# QSPI register map
Vendor: Texas Instruments
Peripheral module from a debugger description file (folder 66AK2G0x_66AK2G1x).
Registers are 32-bit, access not given, reset 0x0 unless marked. A register's access mark holds for its fields unless they carry their own. Offsets are as the file gives them; lines under a group give offsets from that group; [hi:lo] are bit positions; {n}, {i} and the like mark numbered series; 'fields as' and 'values as' point back to an identical list; <NAME> marks a mode.

## QSPI
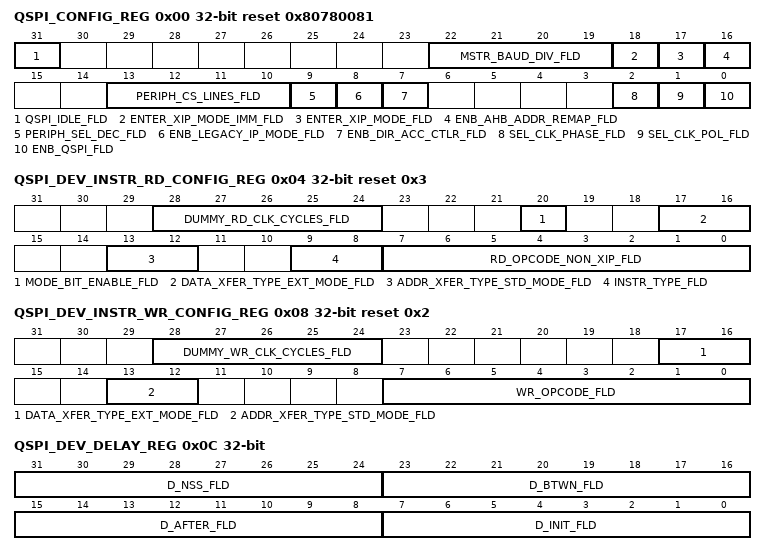
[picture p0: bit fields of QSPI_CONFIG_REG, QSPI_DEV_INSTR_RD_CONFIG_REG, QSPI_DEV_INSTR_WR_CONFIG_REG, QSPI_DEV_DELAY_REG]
0x00 QSPI_CONFIG_REG access per field reset 0x80780081
  [31] QSPI_IDLE_FLD ro — Serial interface and QSPI pipeline is IDLE:
  [22:19] MSTR_BAUD_DIV_FLD rw — Master Mode Baud Rate Divisor (2 to 32): Where Baud Devisor (BD) is:
  [18] ENTER_XIP_MODE_IMM_FLD rw — Enter XIP Mode immediately:
  [17] ENTER_XIP_MODE_FLD rw — Enter XIP Mode on next READ:
  [16] ENB_AHB_ADDR_REMAP_FLD rw — Enable AHB Address Re-mapping (Direct Access Mode Only):
  [13:10] PERIPH_CS_LINES_FLD rw — Peripheral Chip Select Lines:else ss[3:0] directly drives n_ss_out[3:0] .
  [9] PERIPH_SEL_DEC_FLD rw — Peripheral select decode:
  [8] ENB_LEGACY_IP_MODE_FLD rw — Legacy QSPI Mode Enable:
  [7] ENB_DIR_ACC_CTLR_FLD rw — Enable Direct Access Controller:
  [2] SEL_CLK_PHASE_FLD rw — Clock phase:
  [1] SEL_CLK_POL_FLD rw — Clock polarity outside SPI word:
  [0] ENB_QSPI_FLD rw — QSPI Enable:
0x04 QSPI_DEV_INSTR_RD_CONFIG_REG access per field reset 0x3
  [28:24] DUMMY_RD_CLK_CYCLES_FLD rw — Dummy Read Clock Cycles:
  [20] MODE_BIT_ENABLE_FLD rw — Mode Bit Enable:
  [17:16] DATA_XFER_TYPE_EXT_MODE_FLD rw — Data Transfer Type for Standard SPI modes:
  [13:12] ADDR_XFER_TYPE_STD_MODE_FLD rw — Address Transfer Type for Standard SPI modes:
  [9:8] INSTR_TYPE_FLD rw — Instruction Type:
  [7:0] RD_OPCODE_NON_XIP_FLD rw — Read Opcode in non-XIP mode:
0x08 QSPI_DEV_INSTR_WR_CONFIG_REG access per field reset 0x2
  [28:24] DUMMY_WR_CLK_CYCLES_FLD rw — Dummy Write Clock Cycles:
  [17:16] DATA_XFER_TYPE_EXT_MODE_FLD rw — Data Transfer Type for Standard SPI modes:
  [13:12] ADDR_XFER_TYPE_STD_MODE_FLD rw — Address Transfer Type for Standard SPI modes:
  [7:0] WR_OPCODE_FLD rw — Write Opcode:
0x0C QSPI_DEV_DELAY_REG rw
  [31:24] D_NSS_FLD — Clock Delay for Chip Select Deassert:
  [23:16] D_BTWN_FLD — Clock Delay for Chip Select Deactivation:
  [15:8] D_AFTER_FLD — Clock Delay for Last Transaction Bit:
  [7:0] D_INIT_FLD — Clock Delay with n_ss_out:
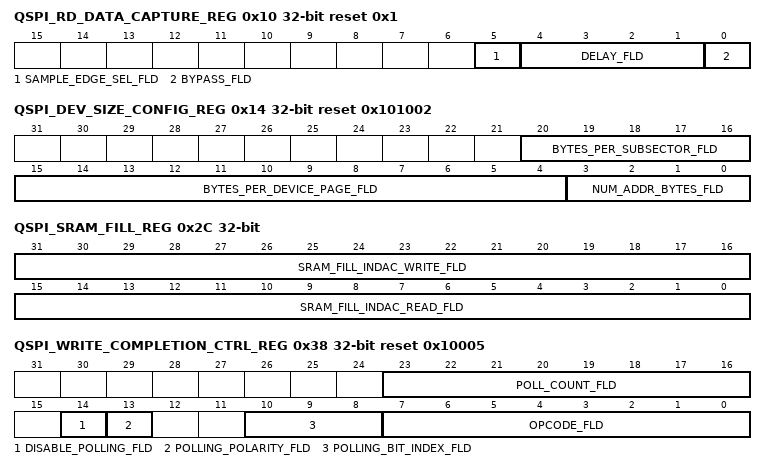
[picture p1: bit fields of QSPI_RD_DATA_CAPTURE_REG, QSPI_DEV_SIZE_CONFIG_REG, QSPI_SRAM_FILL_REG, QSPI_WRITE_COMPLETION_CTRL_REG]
0x10 QSPI_RD_DATA_CAPTURE_REG access per field reset 0x1
  [5] SAMPLE_EDGE_SEL_FLD rw — Sample edge selection (of the flash memory data outputs).
  [4:1] DELAY_FLD rw — Read Delay:
  [0] BYPASS_FLD rw — Bypass:
0x14 QSPI_DEV_SIZE_CONFIG_REG access per field reset 0x101002
  [20:16] BYTES_PER_SUBSECTOR_FLD rw — Number of Bytes per Block:
  [15:4] BYTES_PER_DEVICE_PAGE_FLD rw — Number of Bytes per Device Page:
  [3:0] NUM_ADDR_BYTES_FLD rw — Number of address Bytes:
0x18 QSPI_SRAM_PARTITION_CFG_REG access per field reset 0x80
  [7:0] ADDR_FLD rw — Indirect Read Partition Size:
0x1C QSPI_IND_AHB_ADDR_TRIGGER_REG rw
  [31:0] ADDR_FLD — Indirect Trigger Address:
0x24 QSPI_REMAP_ADDR_REG rw
  [31:0] VALUE_FLD — Remap Address Register:
0x28 QSPI_MODE_BIT_CONFIG_REG access per field
  [7:0] MODE_FLD rw — Mode Bits:
0x2C QSPI_SRAM_FILL_REG ro
  [31:16] SRAM_FILL_INDAC_WRITE_FLD — SRAM Fill Level (Indirect Write Partition):
  [15:0] SRAM_FILL_INDAC_READ_FLD — SRAM Fill Level (Indirect Read Partition):
0x30 QSPI_TX_THRESH_REG access per field reset 0x1
  [3:0] LEVEL_FLD rw — Level TX FIFO not full:
0x34 QSPI_RX_THRESH_REG access per field reset 0x1
  [3:0] LEVEL_FLD rw — Level RX FIFO not empty:
0x38 QSPI_WRITE_COMPLETION_CTRL_REG access per field reset 0x10005
  [23:16] POLL_COUNT_FLD rw — Polling Count:
  [14] DISABLE_POLLING_FLD rw — Disable Polling:
  [13] POLLING_POLARITY_FLD rw — Polling Polarity:
  [10:8] POLLING_BIT_INDEX_FLD rw — Polling Bit Index:
  [7:0] OPCODE_FLD rw — Opcode:
0x3C QSPI_NO_OF_POLLS_BEF_EXP_REG rw reset 0xFFFFFFFF
  [31:0] NO_OF_POLLS_BEF_EXP_FLD — Defines the numbers of polls cycles after which polling expiration interrupt is generated. NOTE: Max no of polls &gt; 2(TX_FIFO_DEPTH – 1) + 1. Polling cycles are queued in FIFO, so expiration requires to make FIFO empty.
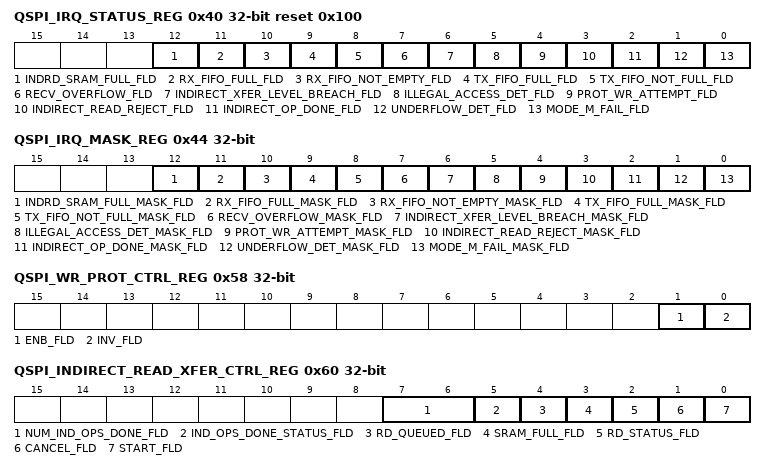
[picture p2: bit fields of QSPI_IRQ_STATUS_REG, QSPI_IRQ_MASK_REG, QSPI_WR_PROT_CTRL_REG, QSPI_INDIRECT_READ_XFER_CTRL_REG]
0x40 QSPI_IRQ_STATUS_REG access per field reset 0x100
  [12] INDRD_SRAM_FULL_FLD rw — Indirect Read Partition overflow:
  [11] RX_FIFO_FULL_FLD rw — Small RX FIFO full:
  [10] RX_FIFO_NOT_EMPTY_FLD rw — Small RX FIFO not empty:
  [9] TX_FIFO_FULL_FLD rw — Small TX FIFO full:
  [8] TX_FIFO_NOT_FULL_FLD rw — Small TX FIFO not full:
  [7] RECV_OVERFLOW_FLD rw — Receive Overflow:
  [6] INDIRECT_XFER_LEVEL_BREACH_FLD rw — Transfer Watermark Breach:
  [5] ILLEGAL_ACCESS_DET_FLD rw — Illegal AHB Access Detected:
  [4] PROT_WR_ATTEMPT_FLD rw — Protected Area Write Attempt:
  [3] INDIRECT_READ_REJECT_FLD rw — Indirect Read Reject:
  [2] INDIRECT_OP_DONE_FLD rw — Indirect Operation Complete:
  [1] UNDERFLOW_DET_FLD rw — Underflow Detected:
  [0] MODE_M_FAIL_FLD rw — Mode M Failure:
0x44 QSPI_IRQ_MASK_REG access per field
  [12] INDRD_SRAM_FULL_MASK_FLD rw — Indirect Read Partition overflow mask
  [11] RX_FIFO_FULL_MASK_FLD rw — Small RX FIFO full Mask
  [10] RX_FIFO_NOT_EMPTY_MASK_FLD rw — Small RX FIFO not empty Mask
  [9] TX_FIFO_FULL_MASK_FLD rw — Small TX FIFO full Mask
  [8] TX_FIFO_NOT_FULL_MASK_FLD rw — Small TX FIFO not full Mask
  [7] RECV_OVERFLOW_MASK_FLD rw — Receive Overflow Mask
  [6] INDIRECT_XFER_LEVEL_BREACH_MASK_FLD rw — Transfer Watermark Breach Mask
  [5] ILLEGAL_ACCESS_DET_MASK_FLD rw — Illegal Access Detected Mask
  [4] PROT_WR_ATTEMPT_MASK_FLD rw — Protected Area Write Attempt Mask
  [3] INDIRECT_READ_REJECT_MASK_FLD rw — Indirect Read Reject Mask
  [2] INDIRECT_OP_DONE_MASK_FLD rw — Indirect Complete Mask
  [1] UNDERFLOW_DET_MASK_FLD rw — Underflow Detected Mask
  [0] MODE_M_FAIL_MASK_FLD rw — Mode M Failure Mask
0x50 QSPI_LOWER_WR_PROT_REG rw
  [31:0] SUBSECTOR_FLD — Lower Block Number:
0x54 QSPI_UPPER_WR_PROT_REG rw
  [31:0] SUBSECTOR_FLD — Upper Block Number:
0x58 QSPI_WR_PROT_CTRL_REG access per field
  [1] ENB_FLD rw — Write Protection Enable Bit:
  [0] INV_FLD rw — Write Protection Inversion Bit:
0x60 QSPI_INDIRECT_READ_XFER_CTRL_REG access per field
  [7:6] NUM_IND_OPS_DONE_FLD ro — Completed Indirect Operations:
  [5] IND_OPS_DONE_STATUS_FLD rw — Indirect Completion Status:
  [4] RD_QUEUED_FLD ro — Queued Indirect Read Operations:
  [3] SRAM_FULL_FLD rw — SRAM Full:
  [2] RD_STATUS_FLD ro — Indirect Read Status:
  [1] CANCEL_FLD wo — Cancel Indirect Read:
  [0] START_FLD wo — Start Indirect Read:
0x64 QSPI_INDIRECT_READ_XFER_WATERMARK_REG rw
  [31:0] LEVEL_FLD — Watermark Value:
0x68 QSPI_INDIRECT_READ_XFER_START_REG rw
  [31:0] ADDR_FLD — Start of Indirect Access:
0x6C QSPI_INDIRECT_READ_XFER_NUM_BYTES_REG rw
  [31:0] VALUE_FLD — Indirect Number of Bytes:
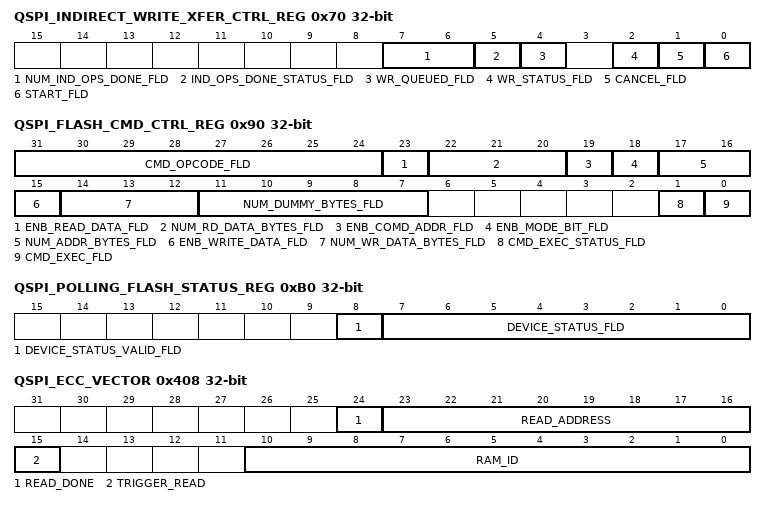
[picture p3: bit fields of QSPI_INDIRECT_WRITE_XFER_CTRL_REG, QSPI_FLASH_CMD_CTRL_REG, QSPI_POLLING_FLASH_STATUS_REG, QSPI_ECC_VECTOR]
0x70 QSPI_INDIRECT_WRITE_XFER_CTRL_REG access per field
  [7:6] NUM_IND_OPS_DONE_FLD ro — Completed Indirect Operations:
  [5] IND_OPS_DONE_STATUS_FLD rw — Indirect Completion Status:
  [4] WR_QUEUED_FLD ro — Queued Indirect Write Operations:
  [2] WR_STATUS_FLD ro — Indirect Write Status:
  [1] CANCEL_FLD wo — Cancel Indirect Write:
  [0] START_FLD wo — Start Indirect Write:
0x74 QSPI_INDIRECT_WRITE_XFER_WATERMARK_REG rw reset 0xFFFFFFFF
  [31:0] LEVEL_FLD — Watermark Value:
0x78 QSPI_INDIRECT_WRITE_XFER_START_REG rw
  [31:0] ADDR_FLD — Start of Indirect Access:
0x7C QSPI_INDIRECT_WRITE_XFER_NUM_BYTES_REG rw
  [31:0] VALUE_FLD — Indirect Number of Bytes:
0x90 QSPI_FLASH_CMD_CTRL_REG access per field
  [31:24] CMD_OPCODE_FLD rw — Command Opcode:
  [23] ENB_READ_DATA_FLD rw — Read Data Enable:
  [22:20] NUM_RD_DATA_BYTES_FLD rw — Number of Read Data Bytes:
  [19] ENB_COMD_ADDR_FLD rw — Command Address Enable:
  [18] ENB_MODE_BIT_FLD rw — Mode Bit Enable:
  [17:16] NUM_ADDR_BYTES_FLD rw — Number of Address Bytes:
  [15] ENB_WRITE_DATA_FLD rw — Write Data Enable:
  [14:12] NUM_WR_DATA_BYTES_FLD rw — Number of Write Data Bytes:
  [11:7] NUM_DUMMY_BYTES_FLD rw — Number of Dummy Bytes:
  [1] CMD_EXEC_STATUS_FLD ro — Command Execution Status:
  [0] CMD_EXEC_FLD wo — Execute Command:
0x94 QSPI_FLASH_CMD_ADDR_REG rw
  [31:0] ADDR_FLD — Command Address:
0xA0 QSPI_FLASH_RD_DATA_LOWER_REG rw
  [31:0] DATA_FLD — Command Read Data (Lower byte):
0xA4 QSPI_FLASH_RD_DATA_UPPER_REG rw
  [31:0] DATA_FLD — Command Read Data (Upper byte):
0xA8 QSPI_FLASH_WR_DATA_LOWER_REG rw
  [31:0] DATA_FLD — Command Write Data Lower Byte:
0xAC QSPI_FLASH_WR_DATA_UPPER_REG rw
  [31:0] DATA_FLD — Command Write Data Upper Byte:
0xB0 QSPI_POLLING_FLASH_STATUS_REG ro
  [8] DEVICE_STATUS_VALID_FLD — Polling Status Valid: This bit is set when value in the
  [7:0] DEVICE_STATUS_FLD — Flash Status: Defines actual Status Register of Device.
0xFC QSPI_MODULE_ID_REG ro reset 0x1010309
  [23:0] VALUE_FLD — Module ID number
0x400 QSPI_ECC_REVISION ro reset 0x4E100001
  [31:0] REV — TI internal data. Identifies revision of peripheral.
0x408 QSPI_ECC_VECTOR access per field
  [24] READ_DONE ro — Status indicating that the read is complete.
  [23:16] READ_ADDRESS rw
  [15] TRIGGER_READ rw — Trigger a read operation to the specified read address.
  [10:0] RAM_ID rw — ECC RAM ID to select which ECC RAM to control or read status from.
0x40C QSPI_ECC_MISC_STATUS ro (reset mask 0xFFFFF800)
  [10:0] NUM_RAMS — Number of ECC RAMs serviced by the aggregator.
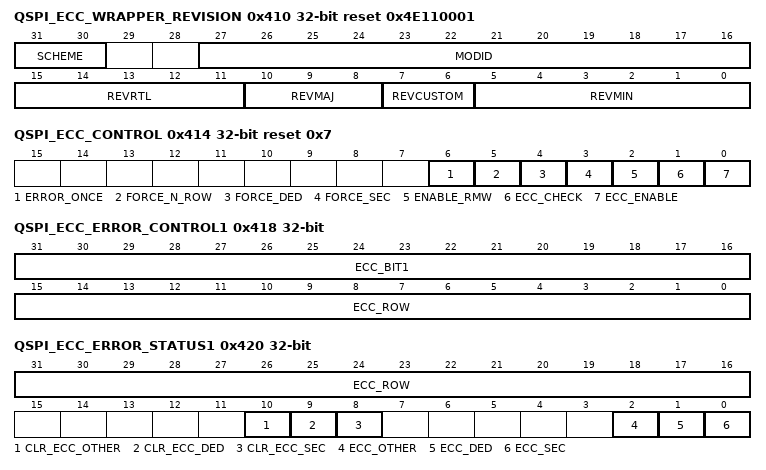
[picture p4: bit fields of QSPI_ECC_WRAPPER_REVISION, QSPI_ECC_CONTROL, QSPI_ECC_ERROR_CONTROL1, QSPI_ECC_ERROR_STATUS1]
0x410 QSPI_ECC_WRAPPER_REVISION ro reset 0x4E110001 (reset mask 0xFFFF07FF)
  [31:30] SCHEME — Scheme that this register is compliant with.
  [27:16] MODID — Module ID
  [15:11] REVRTL — RTL revision
  [10:8] REVMAJ — Major revision
  [7:6] REVCUSTOM — Custom revision
  [5:0] REVMIN — Minor revision
0x414 QSPI_ECC_CONTROL access per field reset 0x7
  [6] ERROR_ONCE rw — If this bit is set, the FORCE_SEC/FORCE_DED will inject an error to the specified row only once. The FORCE_SEC bit will be cleared once a writeback happens. If writeback is not enabled, this error will be cleared the cycle following the read when the data is corrected. For double-bit errors, the FORCE_DED bit will be cleared the cycle following the double-bit error. Any subsequent reads will not force an error.
  [5] FORCE_N_ROW rw — Force single/double-bit error on the next RAM read.
  [4] FORCE_DED rw — Force double-bit error:
  [3] FORCE_SEC rw — Force single-bit error:
  [2] ENABLE_RMW rw — Enable read-modify-write on partial word writes.
  [1] ECC_CHECK rw — Enable ECC check:
  [0] ECC_ENABLE rw — Enable ECC generation.
0x418 QSPI_ECC_ERROR_CONTROL1 rw
  [31:16] ECC_BIT1 — Column/Data bit that needs to be flipped when FORCE_SEC or FORCE_DED is set.
  [15:0] ECC_ROW — Row address where FORCE_SEC or FORCE_DED needs to be applied. This is ignored if FORCE_N_ROW is set.
0x41C QSPI_ECC_ERROR_CONTROL2 access per field
  [15:0] ECC_BIT2 rw — Data bit that needs to be flipped when FORCE_DED is set.
0x420 QSPI_ECC_ERROR_STATUS1
  [31:16] ECC_ROW ro — Indicates the row/address where the single or double-bit error occurred.
  [10] CLR_ECC_OTHER — '1' indicates a successive single-bit error. Writing a ‘1' clears the status bit. (access RW1TC)
  [9] CLR_ECC_DED — '1' indicates a pending double-bit error. Writing a '1' clears the status bit. (access RW1TC)
  [8] CLR_ECC_SEC — '1' indicates a pending single-bit error. Writing a '1' clears the status bit. (access RW1TC)
  [2] ECC_OTHER — '1' – Indicates that successive single-bit errors have occurred while a writeback is still pending. (access RW1TS)
  [1] ECC_DED — '1' – Indicates pending double-bit error status Since the double-bit error from the ECC logic is a pulsed interrupt, this is also a status set register. (access RW1TS)
  [0] ECC_SEC — '1' – Indicates pending single-bit error status Since the single-bit error from the ECC logic is a pulsed interrupt, this is also a status set register. (access RW1TS)
0x424 QSPI_ECC_ERROR_STATUS2 ro
  [15:0] ECC_BIT1 — Indicates the bit position in the ram data that is in error. For example: a value of 1 indicates that bit 1 in the data is in error. This is valid only for single bit errors (sec).
0x43C QSPI_ECC_EOI
  [0] EOI_WR — Write to this register indicates that software has acknowledged the pending interrupt and the next interrupt can be sent to the host. (access W1TS)
{0x440+4i} QSPI_ECC_INT_STATUS_{i} ro (i=0..14)
  [31:0] BITMASK — Level interrupt status from each ECC RAM.
{0x480+4i} QSPI_ECC_INT_ENABLE_{i} (i=0..14)
  [31:0] BITMASK — Write 1 to enable interrupt from the associated ECC RAM. (access W1TS)
{0x4C0+4i} QSPI_ECC_INT_CLEAR_{i} (i=0..14)
  [31:0] BITMASK — Write 1 to disable interrupt from the associated ECC RAM. (access W1TC)
